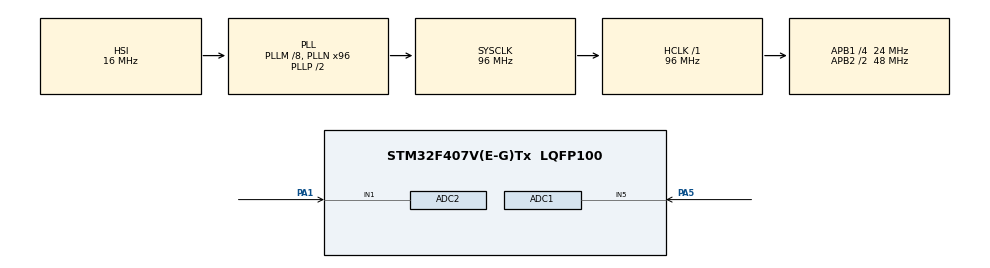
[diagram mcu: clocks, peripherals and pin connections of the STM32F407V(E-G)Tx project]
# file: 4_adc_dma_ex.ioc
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ADC1.Channel-0\#ChannelRegularConversion=ADC_CHANNEL_VREFINT
ADC1.Channel-1\#ChannelRegularConversion=ADC_CHANNEL_5
ADC1.Channel-2\#ChannelRegularConversion=ADC_CHANNEL_TEMPSENSOR
ADC1.ContinuousConvMode=ENABLE
ADC1.DMAContinuousRequests=ENABLE
ADC1.NbrOfConversion=3
ADC1.NbrOfConversionFlag=1
ADC1.Rank-0\#ChannelRegularConversion=1
ADC1.Rank-1\#ChannelRegularConversion=2
ADC1.Rank-2\#ChannelRegularConversion=3
ADC1.SamplingTime-0\#ChannelRegularConversion=ADC_SAMPLETIME_480CYCLES
ADC1.SamplingTime-1\#ChannelRegularConversion=ADC_SAMPLETIME_480CYCLES
ADC1.SamplingTime-2\#ChannelRegularConversion=ADC_SAMPLETIME_480CYCLES
ADC1.ScanConvMode=ENABLE
ADC1.master=1
ADC2.Channel-0\#ChannelRegularConversion=ADC_CHANNEL_1
ADC2.ContinuousConvMode=ENABLE
ADC2.DMAContinuousRequests=ENABLE
ADC2.NbrOfConversion=1
ADC2.NbrOfConversionFlag=1
ADC2.Rank-0\#ChannelRegularConversion=1
ADC2.SamplingTime-0\#ChannelRegularConversion=ADC_SAMPLETIME_480CYCLES
Dma.ADC1.0.Direction=DMA_PERIPH_TO_MEMORY
Dma.ADC1.0.FIFOMode=DMA_FIFOMODE_DISABLE
Dma.ADC1.0.Instance=DMA2_Stream0
Dma.ADC1.0.MemDataAlignment=DMA_MDATAALIGN_HALFWORD
Dma.ADC1.0.MemInc=DMA_MINC_ENABLE
Dma.ADC1.0.Mode=DMA_CIRCULAR
Dma.ADC1.0.PeriphDataAlignment=DMA_PDATAALIGN_HALFWORD
Dma.ADC1.0.PeriphInc=DMA_PINC_DISABLE
Dma.ADC1.0.Priority=DMA_PRIORITY_LOW
Dma.ADC2.1.Direction=DMA_PERIPH_TO_MEMORY
Dma.ADC2.1.FIFOMode=DMA_FIFOMODE_DISABLE
Dma.ADC2.1.Instance=DMA2_Stream3
Dma.ADC2.1.MemDataAlignment=DMA_MDATAALIGN_HALFWORD
Dma.ADC2.1.MemInc=DMA_MINC_ENABLE
Dma.ADC2.1.Mode=DMA_CIRCULAR
Dma.ADC2.1.PeriphDataAlignment=DMA_PDATAALIGN_HALFWORD
Dma.ADC2.1.PeriphInc=DMA_PINC_DISABLE
Dma.ADC2.1.Priority=DMA_PRIORITY_LOW
Dma.Request0=ADC1
Dma.Request1=ADC2
Mcu.Family=STM32F4
Mcu.Name=STM32F407V(E-G)Tx
Mcu.Package=LQFP100
NVIC.DMA2_Stream0_IRQn=true\:0\:0\:false\:false\:true\:false
NVIC.DMA2_Stream3_IRQn=true\:0\:0\:false\:false\:true\:false
NVIC.PriorityGroup=NVIC_PRIORITYGROUP_4
PA1.Signal=ADCx_IN1
PA13.Mode=Serial_Wire
PA13.Signal=SYS_JTMS-SWDIO
PA14.Mode=Serial_Wire
PA14.Signal=SYS_JTCK-SWCLK
PA5.Signal=ADCx_IN5
ProjectManager.HeapSize=0x200
ProjectManager.StackSize=0x400
ProjectManager.TargetToolchain=MDK-ARM V5
RCC.48MHZClocksFreq_Value=48000000
RCC.AHBFreq_Value=96000000
RCC.APB1CLKDivider=RCC_HCLK_DIV4
RCC.APB1Freq_Value=24000000
RCC.APB1TimFreq_Value=48000000
RCC.APB2CLKDivider=RCC_HCLK_DIV2
RCC.APB2Freq_Value=48000000
RCC.APB2TimFreq_Value=96000000
RCC.CortexFreq_Value=96000000
RCC.HCLKFreq_Value=96000000
RCC.HSE_VALUE=25000000
RCC.HSI_VALUE=16000000
RCC.LSE_VALUE=32768
RCC.PLLM=8
RCC.PLLN=96
RCC.SYSCLKFreq_VALUE=96000000
RCC.SYSCLKSource=RCC_SYSCLKSOURCE_PLLCLK
RCC.VCOOutputFreq_Value=192000000
SH.ADCx_IN1.0=ADC2_IN1,IN1
SH.ADCx_IN5.0=ADC1_IN5,IN5
VP_ADC1_TempSens_Input.Mode=IN-TempSens
VP_ADC1_Vref_Input.Mode=IN-Vrefint
board=4_adc_dma_ex

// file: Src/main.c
/**
  ******************************************************************************
  * File Name          : main.c
  * Description        : Main program body
  ******************************************************************************
  ** This notice applies to any and all portions of this file
  * that are not between comment pairs USER CODE BEGIN and
  * USER CODE END. Other portions of this file, whether
  * inserted by the user or by software development tools
  * are owned by their respective copyright owners.
  *
  * COPYRIGHT(c) 2018 STMicroelectronics
  *
  * Redistribution and use in source and binary forms, with or without modification,
  * are permitted provided that the following conditions are met:
  *   1. Redistributions of source code must retain the above copyright notice,
  *      this list of conditions and the following disclaimer.
  *   2. Redistributions in binary form must reproduce the above copyright notice,
  *      this list of conditions and the following disclaimer in the documentation
  *      and/or other materials provided with the distribution.
  *   3. Neither the name of STMicroelectronics nor the names of its contributors
  *      may be used to endorse or promote products derived from this software
  *      without specific prior written permission.
  *
  * THIS SOFTWARE IS PROVIDED BY THE COPYRIGHT HOLDERS AND CONTRIBUTORS "AS IS"
  * AND ANY EXPRESS OR IMPLIED WARRANTIES, INCLUDING, BUT NOT LIMITED TO, THE
  * IMPLIED WARRANTIES OF MERCHANTABILITY AND FITNESS FOR A PARTICULAR PURPOSE ARE
  * DISCLAIMED. IN NO EVENT SHALL THE COPYRIGHT HOLDER OR CONTRIBUTORS BE LIABLE
  * FOR ANY DIRECT, INDIRECT, INCIDENTAL, SPECIAL, EXEMPLARY, OR CONSEQUENTIAL
  * DAMAGES (INCLUDING, BUT NOT LIMITED TO, PROCUREMENT OF SUBSTITUTE GOODS OR
  * SERVICES; LOSS OF USE, DATA, OR PROFITS; OR BUSINESS INTERRUPTION) HOWEVER
  * CAUSED AND ON ANY THEORY OF LIABILITY, WHETHER IN CONTRACT, STRICT LIABILITY,
  * OR TORT (INCLUDING NEGLIGENCE OR OTHERWISE) ARISING IN ANY WAY OUT OF THE USE
  * OF THIS SOFTWARE, EVEN IF ADVISED OF THE POSSIBILITY OF SUCH DAMAGE.
  *
  ******************************************************************************
  */
#include "main.h"
#include "stm32f4xx_hal.h"

ADC_HandleTypeDef hadc1;
ADC_HandleTypeDef hadc2;
DMA_HandleTypeDef hdma_adc1;
DMA_HandleTypeDef hdma_adc2;

/* USER CODE BEGIN PV */
/* Private variables ---------------------------------------------------------*/
#define VREFIN_CAL ((uint16_t*)(uint32_t) 0x1FFF7A2A)  // vrefin cal degerinin adresi..
#define V25 (float) 0.76 // volt
#define avg_slope (float) 0.0025 // volt/Centigrade

uint16_t adc1_data[3],adc2_data[1];
float Vadc1_ch5=0, Vadc2_ch1=0, Vref=0,Vsense=0,temperature=0;
// unsigned char count=0; // bu kullanilmayacak dma degerleri kendi atayacak.

/* USER CODE END PV */

void SystemClock_Config(void);
static void MX_GPIO_Init(void);
static void MX_DMA_Init(void);
static void MX_ADC1_Init(void);
static void MX_ADC2_Init(void);

/* USER CODE BEGIN PFP */
/* Private function prototypes -----------------------------------------------*/
  void HAL_ADC_ConvCpltCallback(ADC_HandleTypeDef* hadc)
	{
	  Vref=(float)3.3*(*VREFIN_CAL)/adc1_data[0];
		Vadc1_ch5=Vref*adc1_data[1]/4095;
		Vsense=Vref*adc1_data[2]/4095;

		Vadc2_ch1=Vref*adc2_data[0]/4095;

	  temperature=(Vsense-V25)/avg_slope+25;

	  // önceden countta 0 1 2 diye yaziyorduk.
		// count'a gerek yok çünkü dma onu hallediyor Interrupt ile yapilan modda kullaniyor idik

	}
/* USER CODE END PFP */

int main(void)
{

  /* MCU Configuration----------------------------------------------------------*/

  /* Reset of all peripherals, Initializes the Flash interface and the Systick. */
  HAL_Init();

  /* Configure the system clock */
  SystemClock_Config();

  /* Initialize all configured peripherals */
  MX_GPIO_Init();
  MX_DMA_Init();
  MX_ADC1_Init();
  MX_ADC2_Init();

	// baslattik. continuos mod oldugu için tekrar baslatmaya gerek yok.
 HAL_ADC_Start_DMA(&hadc1,(uint32_t*)adc1_data, 3); // 32 bitlik istedigi için 32 bit e çevirdik.
 // dma  sirasiyla 3 tane deger okuyacak . adc1_data degiskenine
 HAL_ADC_Start_DMA(&hadc2,(uint32_t*)adc2_data, 1); // dizi olarak belirttik yukarda.
  /* Infinite loop */
  while (1)
  {

  }

}

/** System Clock Configuration
*/
void SystemClock_Config(void)
{

  RCC_OscInitTypeDef RCC_OscInitStruct;
  RCC_ClkInitTypeDef RCC_ClkInitStruct;

    /**Configure the main internal regulator output voltage
    */
  __HAL_RCC_PWR_CLK_ENABLE();

  __HAL_PWR_VOLTAGESCALING_CONFIG(PWR_REGULATOR_VOLTAGE_SCALE1);

    /**Initializes the CPU, AHB and APB busses clocks
    */
  RCC_OscInitStruct.OscillatorType = RCC_OSCILLATORTYPE_HSI;
  RCC_OscInitStruct.HSIState = RCC_HSI_ON;
  RCC_OscInitStruct.HSICalibrationValue = 16;
  RCC_OscInitStruct.PLL.PLLState = RCC_PLL_ON;
  RCC_OscInitStruct.PLL.PLLSource = RCC_PLLSOURCE_HSI;
  RCC_OscInitStruct.PLL.PLLM = 8;
  RCC_OscInitStruct.PLL.PLLN = 96;
  RCC_OscInitStruct.PLL.PLLP = RCC_PLLP_DIV2;
  RCC_OscInitStruct.PLL.PLLQ = 4;
  if (HAL_RCC_OscConfig(&RCC_OscInitStruct) != HAL_OK)
  {
    _Error_Handler(__FILE__, __LINE__);
  }

    /**Initializes the CPU, AHB and APB busses clocks
    */
  RCC_ClkInitStruct.ClockType = RCC_CLOCKTYPE_HCLK|RCC_CLOCKTYPE_SYSCLK
                              |RCC_CLOCKTYPE_PCLK1|RCC_CLOCKTYPE_PCLK2;
  RCC_ClkInitStruct.SYSCLKSource = RCC_SYSCLKSOURCE_PLLCLK;
  RCC_ClkInitStruct.AHBCLKDivider = RCC_SYSCLK_DIV1;
  RCC_ClkInitStruct.APB1CLKDivider = RCC_HCLK_DIV4;
  RCC_ClkInitStruct.APB2CLKDivider = RCC_HCLK_DIV2;

  if (HAL_RCC_ClockConfig(&RCC_ClkInitStruct, FLASH_LATENCY_3) != HAL_OK)
  {
    _Error_Handler(__FILE__, __LINE__);
  }

    /**Configure the Systick interrupt time
    */
  HAL_SYSTICK_Config(HAL_RCC_GetHCLKFreq()/1000);

    /**Configure the Systick
    */
  HAL_SYSTICK_CLKSourceConfig(SYSTICK_CLKSOURCE_HCLK);

  /* SysTick_IRQn interrupt configuration */
  HAL_NVIC_SetPriority(SysTick_IRQn, 0, 0);
}

/* ADC1 init function */
static void MX_ADC1_Init(void)
{

  ADC_ChannelConfTypeDef sConfig;

    /**Configure the global features of the ADC (Clock, Resolution, Data Alignment and number of conversion)
    */
  hadc1.Instance = ADC1;
  hadc1.Init.ClockPrescaler = ADC_CLOCK_SYNC_PCLK_DIV2;
  hadc1.Init.Resolution = ADC_RESOLUTION_12B;
  hadc1.Init.ScanConvMode = ENABLE;
  hadc1.Init.ContinuousConvMode = ENABLE;
  hadc1.Init.DiscontinuousConvMode = DISABLE;
  hadc1.Init.ExternalTrigConvEdge = ADC_EXTERNALTRIGCONVEDGE_NONE;
  hadc1.Init.ExternalTrigConv = ADC_SOFTWARE_START;
  hadc1.Init.DataAlign = ADC_DATAALIGN_RIGHT;
  hadc1.Init.NbrOfConversion = 3;
  hadc1.Init.DMAContinuousRequests = ENABLE;
  hadc1.Init.EOCSelection = ADC_EOC_SINGLE_CONV;
  if (HAL_ADC_Init(&hadc1) != HAL_OK)
  {
    _Error_Handler(__FILE__, __LINE__);
  }

    /**Configure for the selected ADC regular channel its corresponding rank in the sequencer and its sample time.
    */
  sConfig.Channel = ADC_CHANNEL_VREFINT;
  sConfig.Rank = 1;
  sConfig.SamplingTime = ADC_SAMPLETIME_480CYCLES;
  if (HAL_ADC_ConfigChannel(&hadc1, &sConfig) != HAL_OK)
  {
    _Error_Handler(__FILE__, __LINE__);
  }

    /**Configure for the selected ADC regular channel its corresponding rank in the sequencer and its sample time.
    */
  sConfig.Channel = ADC_CHANNEL_5;
  sConfig.Rank = 2;
  if (HAL_ADC_ConfigChannel(&hadc1, &sConfig) != HAL_OK)
  {
    _Error_Handler(__FILE__, __LINE__);
  }

    /**Configure for the selected ADC regular channel its corresponding rank in the sequencer and its sample time.
    */
  sConfig.Channel = ADC_CHANNEL_TEMPSENSOR;
  sConfig.Rank = 3;
  if (HAL_ADC_ConfigChannel(&hadc1, &sConfig) != HAL_OK)
  {
    _Error_Handler(__FILE__, __LINE__);
  }

}

/* ADC2 init function */
static void MX_ADC2_Init(void)
{

  ADC_ChannelConfTypeDef sConfig;

    /**Configure the global features of the ADC (Clock, Resolution, Data Alignment and number of conversion)
    */
  hadc2.Instance = ADC2;
  hadc2.Init.ClockPrescaler = ADC_CLOCK_SYNC_PCLK_DIV2;
  hadc2.Init.Resolution = ADC_RESOLUTION_12B;
  hadc2.Init.ScanConvMode = DISABLE;
  hadc2.Init.ContinuousConvMode = ENABLE;
  hadc2.Init.DiscontinuousConvMode = DISABLE;
  hadc2.Init.ExternalTrigConvEdge = ADC_EXTERNALTRIGCONVEDGE_NONE;
  hadc2.Init.ExternalTrigConv = ADC_SOFTWARE_START;
  hadc2.Init.DataAlign = ADC_DATAALIGN_RIGHT;
  hadc2.Init.NbrOfConversion = 1;
  hadc2.Init.DMAContinuousRequests = ENABLE;
  hadc2.Init.EOCSelection = ADC_EOC_SINGLE_CONV;
  if (HAL_ADC_Init(&hadc2) != HAL_OK)
  {
    _Error_Handler(__FILE__, __LINE__);
  }

    /**Configure for the selected ADC regular channel its corresponding rank in the sequencer and its sample time.
    */
  sConfig.Channel = ADC_CHANNEL_1;
  sConfig.Rank = 1;
  sConfig.SamplingTime = ADC_SAMPLETIME_480CYCLES;
  if (HAL_ADC_ConfigChannel(&hadc2, &sConfig) != HAL_OK)
  {
    _Error_Handler(__FILE__, __LINE__);
  }

}

static void MX_DMA_Init(void)
{
  /* DMA controller clock enable */
  __HAL_RCC_DMA2_CLK_ENABLE();

  /* DMA interrupt init */
  /* DMA2_Stream0_IRQn interrupt configuration */
  HAL_NVIC_SetPriority(DMA2_Stream0_IRQn, 0, 0);
  HAL_NVIC_EnableIRQ(DMA2_Stream0_IRQn);
  /* DMA2_Stream3_IRQn interrupt configuration */
  HAL_NVIC_SetPriority(DMA2_Stream3_IRQn, 0, 0);
  HAL_NVIC_EnableIRQ(DMA2_Stream3_IRQn);

}

/** Configure pins as
        * Analog
        * Input
        * Output
        * EVENT_OUT
        * EXTI
*/
static void MX_GPIO_Init(void)
{

  /* GPIO Ports Clock Enable */
  __HAL_RCC_GPIOA_CLK_ENABLE();

}

void _Error_Handler(char * file, int line)
{
  while(1)
  {
  }
}

/************************ (C) COPYRIGHT STMicroelectronics *****END OF FILE****/
